# STM32MP153 register map
File version: 1.4
CPU: CM4 r0p1, little endian, no MPU, FPU, 4 interrupt priority bits
Registers are 32-bit, read-write, reset 0x0 unless marked. A register's access mark holds for its fields unless they carry their own. Offsets are from the block's base; [hi:lo] are bit positions; {n}, {i} and the like mark numbered series.

## GICH
Base 0xA0024000
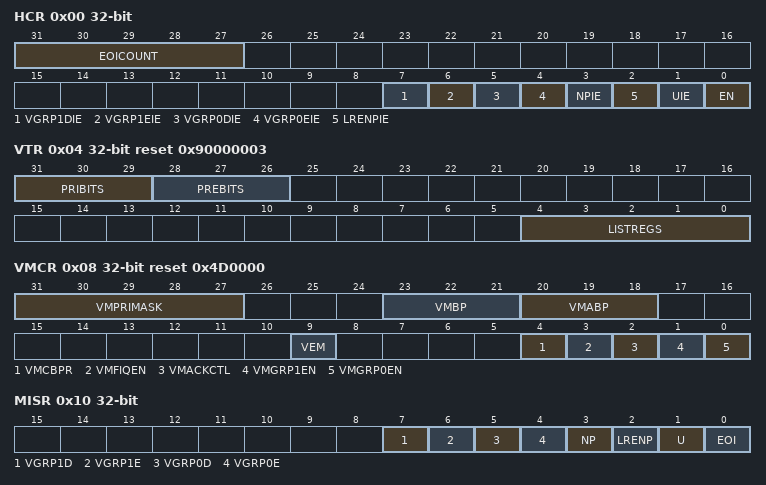
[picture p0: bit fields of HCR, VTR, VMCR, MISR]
0x00 HCR — GICH hypervisor control register
  [31:27] EOICOUNT, [7] VGRP1DIE, [6] VGRP1EIE, [5] VGRP0DIE, [4] VGRP0EIE, [3] NPIE, [2] LRENPIE, [1] UIE, [0] EN
0x04 VTR ro reset 0x90000003 — GICH VGIC type register
  [31:29] PRIBITS, [28:26] PREBITS, [4:0] LISTREGS
0x08 VMCR reset 0x4D0000 — GICH virtual machine control register
  [31:27] VMPRIMASK, [23:21] VMBP, [20:18] VMABP, [9] VEM, [4] VMCBPR, [3] VMFIQEN, [2] VMACKCTL, [1] VMGRP1EN, [0] VMGRP0EN
0x10 MISR ro — GICH maintenance interrupt status register
  [7] VGRP1D, [6] VGRP1E, [5] VGRP0D, [4] VGRP0E, [3] NP, [2] LRENP, [1] U, [0] EOI
0x20 EISR0 ro — GICH end of interrupt status register
0x30 ELSR0 ro reset 0xF — GICH empty list status register
0xF0 APR0 — GICH active priority register
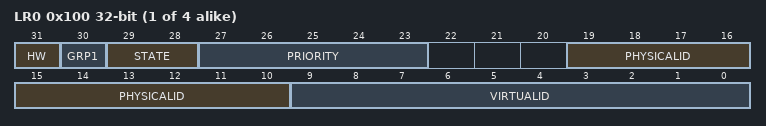
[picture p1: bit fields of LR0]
{0x100+4i} LR{i} (i=0..3) — GICH list register {i}
  [31] HW, [30] GRP1, [29:28] STATE, [27:23] PRIORITY, [19:10] PHYSICALID, [9:0] VIRTUALID

## GICV
Base 0xA0026000
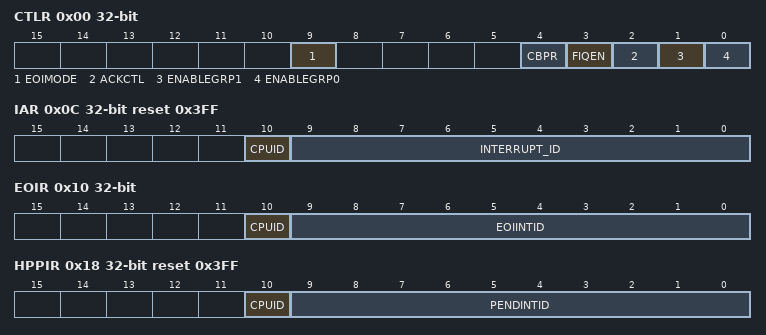
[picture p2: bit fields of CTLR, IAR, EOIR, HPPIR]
0x00 CTLR — GICV virtual machine control register
  [9] EOIMODE, [4] CBPR, [3] FIQEN, [2] ACKCTL, [1] ENABLEGRP1, [0] ENABLEGRP0
0x04 PMR — GICV VM priority mask register
  [7:3] PRIORITY
0x08 BPR reset 0x2 — GICV VM binary point register
  [2:0] BINARY_POINT
0x0C IAR ro reset 0x3FF — GICV VM interrupt acknowledge register
  [10] CPUID, [9:0] INTERRUPT_ID
0x10 EOIR wo — GICV VM end of interrupt register
  [10] CPUID, [9:0] EOIINTID
0x14 RPR ro reset 0xFF — GICV VM running priority register
  [7:3] PRIORITY
0x18 HPPIR ro reset 0x3FF — GICV VM highest priority pending interrupt register
  [10] CPUID, [9:0] PENDINTID
0x1C ABPR reset 0x3 — GICV VM aliased binary point register
  [2:0] BINARY_POINT
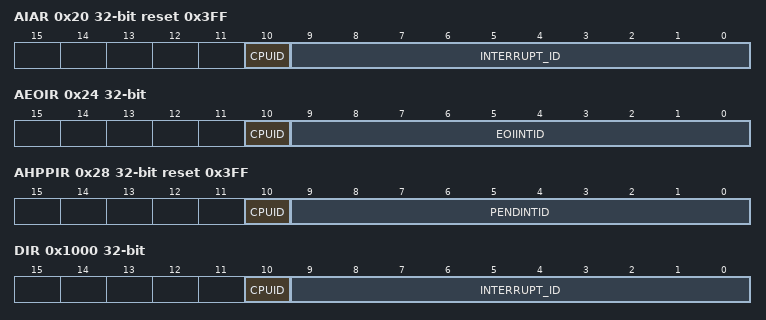
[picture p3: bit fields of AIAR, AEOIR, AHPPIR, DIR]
0x20 AIAR ro reset 0x3FF — GICV VM aliased interrupt register
  [10] CPUID, [9:0] INTERRUPT_ID
0x24 AEOIR wo — GICV VM aliased end of interrupt register
  [10] CPUID, [9:0] EOIINTID
0x28 AHPPIR ro reset 0x3FF — GICV VM aliased highest priority pending interrupt register
  [10] CPUID, [9:0] PENDINTID
0xD0 APR0 — The GICV_APR0 is an alias of GICH_APR.
0xFC IIDR ro reset 0x102143B — The GICV_IIDR is an alias of GICC_IIDR.
0x1000 DIR wo — GICV VM deactivate interrupt register
  [10] CPUID, [9:0] INTERRUPT_ID

## HASH1 — HASH register block
Base 0x54002000
Same registers: HASH2 0x4C002000
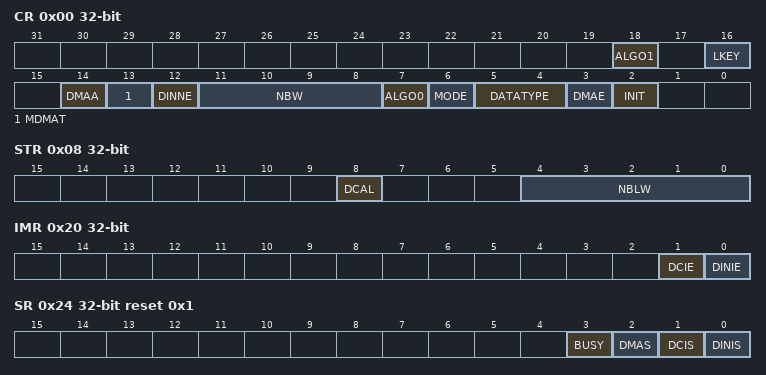
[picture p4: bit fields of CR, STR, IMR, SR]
0x00 CR access per field — HASH control register
  [18] ALGO1 rw, [16] LKEY rw, [14] DMAA wo, [13] MDMAT rw, [12] DINNE ro, [11:8] NBW ro, [7] ALGO0 rw, [6] MODE rw, [5:4] DATATYPE rw, [3] DMAE rw, [2] INIT wo
0x04 DIN — HASH_DIN is the data input register.
  [31:0] DATAIN
0x08 STR access per field — The HASH_STR register has two functions: It is used to define the number of valid bits in the last word of the message entered in the hash processor (that is the number of valid least significant bits in the last data written to the HASH_DIN register) It is used to start the processing of the last block in the message by writing the DCAL bit to 1
  [8] DCAL wo, [4:0] NBLW rw
{0xC+4i} HR{i} ro (i=0..4) — HASH digest register {i}
  [31:0] H{i}
0x20 IMR — HASH interrupt enable register
  [1] DCIE, [0] DINIE
0x24 SR access per field reset 0x1 — HASH status register
  [3] BUSY ro, [2] DMAS ro, [1] DCIS rw, [0] DINIS rw
0xF8 CSR0 reset 0x2 — These registers contain the complete internal register states of the hash processor. They are useful when a context swap has to be done because a high-priority task needs to use the hash processor while it is already used by another task. When such an event occurs, the HASH_CSRx registers have to be read and the read values have to be saved in the system memory space. Then the hash processor can be used by the preemptive task, and when the hash computation is complete, the saved context can be read from memory and written back into the HASH_CSRx registers.
  [31:0] CS0
{0xF8+4i} CSR{i} (i=1..53) — HASH context swap registers
  [31:0] CS{i}
{0x310+4i} HR{i} ro (i=5..7) — HASH digest register {i}
  [31:0] H{i}
0x3F0 HWCFGR ro reset 0x1 — HASH Hardware Configuration Register
  [3:0] CFG1
0x3F4 VERR ro reset 0x23 — HASH Version Register
  [7:0] VER
0x3F8 IPIDR ro reset 0x170031 — HASH Identification
  [31:0] ID
0x3FC MID ro reset 0xA3C5DD01 — HASH Hardware Magic ID
